VERSION ""

NS_ :

BU_: EBCM ADAS PCM EPS VSA SCM BDY XXX EPB EON

BO_ 145 KINEMATICS: 8 XXX
 SG_ LAT_ACCEL : 7|10@0+ (0.02,-512) [-20|20] "m/s2" EON

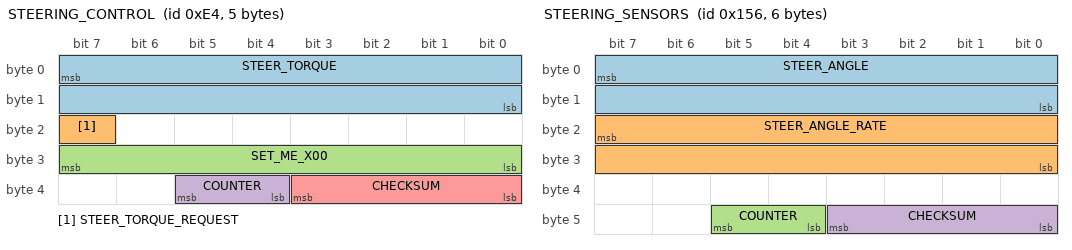
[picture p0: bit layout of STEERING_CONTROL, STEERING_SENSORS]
BO_ 228 STEERING_CONTROL: 5 ADAS
 SG_ STEER_TORQUE : 7|16@0- (1,0) [-3840|3840] "" EPS
 SG_ STEER_TORQUE_REQUEST : 23|1@0+ (1,0) [0|1] "" EPS
 SG_ SET_ME_X00 : 31|8@0+ (1,0) [0|0] "" EPS
 SG_ COUNTER : 37|2@0+ (1,0) [0|3] "" EPS
 SG_ CHECKSUM : 35|4@0+ (1,0) [0|3] "" EPS

//BO_ 304 GAS_PEDAL_2: 8 PCM
 //SG_ ENGINE_TORQUE_ESTIMATE : 7|16@0- (1,0) [-1000|1000] "Nm" EON
// SG_ ENGINE_TORQUE_REQUEST : 23|16@0- (1,0) [-1000|1000] "Nm" EON
// SG_ CAR_GAS : 39|8@0+ (1,0) [0|255] "" EON

BO_ 308 GAS_PEDAL_3: 8 XXX
 SG_ PEDAL_GAS_VARIANT : 19|12@0+ (1,0) [0|2048] "" XXX

BO_ 316 GAS_PEDAL: 8 PCM
 SG_ ENGINE_TORQUE_ESTIMATE : 7|16@0- (1,0) [-1000|1000] "Nm" EON
 SG_ ENGINE_TORQUE_REQUEST : 23|16@0- (1,0) [-1000|1000] "Nm" EON
 SG_ CAR_GAS : 39|8@0+ (1,0) [0|255] "" EON

BO_ 342 STEERING_SENSORS: 6 EPS
 SG_ STEER_ANGLE : 7|16@0- (-0.1,0) [-500|500] "deg" EON
 SG_ STEER_ANGLE_RATE : 23|16@0- (1,0) [-3000|3000] "deg/s" EON
 SG_ COUNTER : 45|2@0+ (1,0) [0|3] "" EON
 SG_ CHECKSUM : 43|4@0+ (1,0) [0|3] "" EON

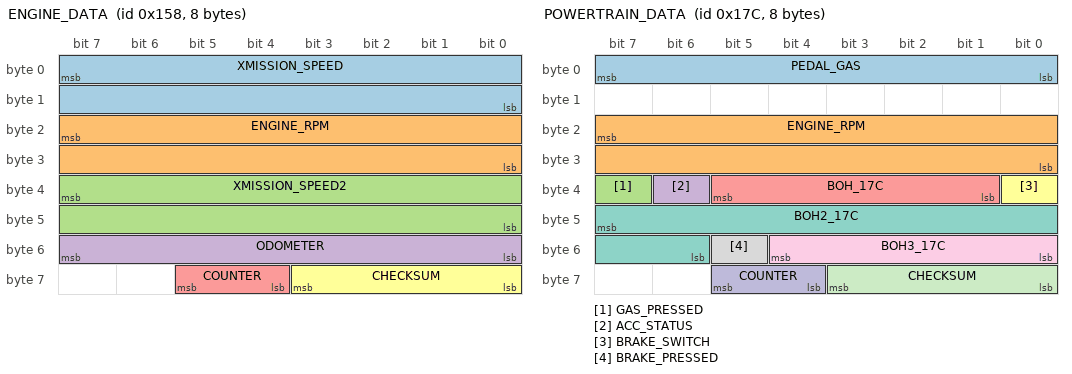
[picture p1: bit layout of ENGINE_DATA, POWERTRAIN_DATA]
BO_ 344 ENGINE_DATA: 8 PCM
 SG_ XMISSION_SPEED : 7|16@0+ (0.01,0) [0|250] "kph" EON
 SG_ ENGINE_RPM : 23|16@0+ (1,0) [0|15000] "rpm" EON
 SG_ XMISSION_SPEED2 : 39|16@0+ (0.01,0) [0|250] "kph" EON
 SG_ ODOMETER : 55|8@0+ (10,0) [0|2550] "m" XXX
 SG_ COUNTER : 61|2@0+ (1,0) [0|3] "" EON
 SG_ CHECKSUM : 59|4@0+ (1,0) [0|15] "" EON

BO_ 380 POWERTRAIN_DATA: 8 PCM
 SG_ PEDAL_GAS : 7|8@0+ (1,0) [0|255] "" EON
 SG_ ENGINE_RPM : 23|16@0+ (1,0) [0|15000] "rpm" EON
 SG_ GAS_PRESSED : 39|1@0+ (1,0) [0|1] "" EON
 SG_ ACC_STATUS : 38|1@0+ (1,0) [0|1] "rpm" EON
 SG_ BOH_17C : 37|5@0+ (1,0) [0|1] "rpm" EON
 SG_ BRAKE_SWITCH : 32|1@0+ (1,0) [0|1] "rpm" EON
 SG_ BOH2_17C : 47|10@0+ (1,0) [0|1] "rpm" EON
 SG_ BRAKE_PRESSED : 53|1@0+ (1,0) [0|1] "" EON
 SG_ BOH3_17C : 52|5@0+ (1,0) [0|1] "rpm" EON
 SG_ COUNTER : 61|2@0+ (1,0) [0|3] "" EON
 SG_ CHECKSUM : 59|4@0+ (1,0) [0|3] "" EON

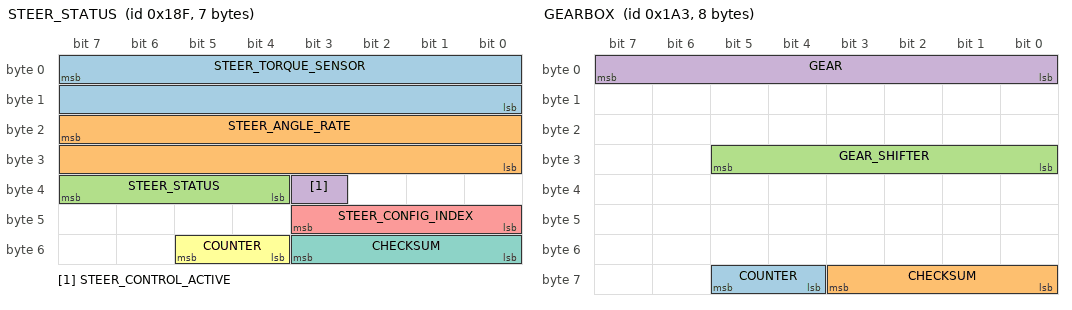
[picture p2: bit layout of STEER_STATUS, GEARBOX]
BO_ 399 STEER_STATUS: 7 EPS
 SG_ STEER_TORQUE_SENSOR : 7|16@0- (-1,0) [-31000|31000] "tbd" EON
 SG_ STEER_ANGLE_RATE : 23|16@0- (-0.1,0) [-31000|31000] "deg/s" EON
 SG_ STEER_STATUS : 39|4@0+ (1,0) [0|15] "" EON
 SG_ STEER_CONTROL_ACTIVE : 35|1@0+ (1,0) [0|1] "" EON
 SG_ STEER_CONFIG_INDEX : 43|4@0+ (1,0) [0|15] "" EON
 SG_ COUNTER : 53|2@0+ (1,0) [0|3] "" EON
 SG_ CHECKSUM : 51|4@0+ (1,0) [0|3] "" EON

BO_ 419 GEARBOX: 8 PCM
 SG_ COUNTER : 61|2@0+ (1,0) [0|3] "" EON
 SG_ CHECKSUM : 59|4@0+ (1,0) [0|3] "" EON
 SG_ GEAR_SHIFTER : 29|6@0+ (1,0) [0|63] "" EON
 SG_ GEAR : 7|8@0+ (1,0) [0|255] "" EON

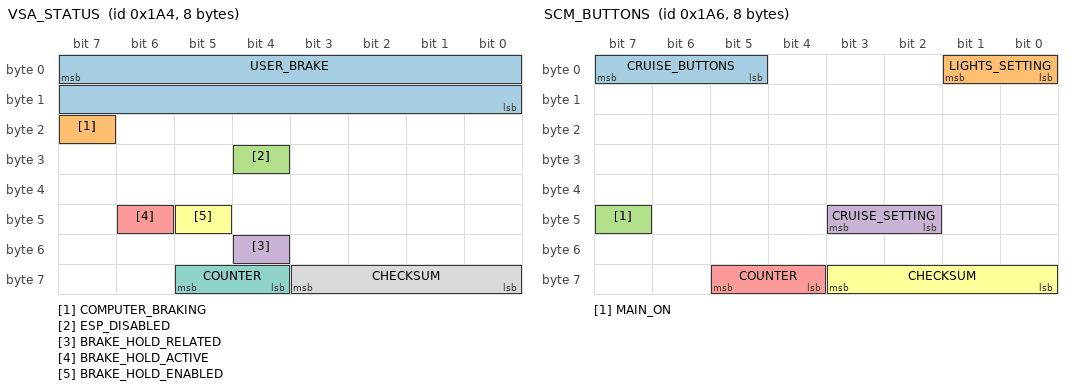
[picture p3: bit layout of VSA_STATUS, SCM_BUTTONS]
BO_ 420 VSA_STATUS: 8 VSA
 SG_ USER_BRAKE : 7|16@0+ (0.015625,-1.609375) [0|1000] "" EON
 SG_ COMPUTER_BRAKING : 23|1@0+ (1,0) [0|1] "" EON
 SG_ ESP_DISABLED : 28|1@0+ (1,0) [0|1] "" EON
 SG_ BRAKE_HOLD_RELATED : 52|1@0+ (1,0) [0|1] "" XXX
 SG_ BRAKE_HOLD_ACTIVE : 46|1@0+ (1,0) [0|1] "" EON
 SG_ BRAKE_HOLD_ENABLED : 45|1@0+ (1,0) [0|1] "" EON
 SG_ COUNTER : 61|2@0+ (1,0) [0|3] "" EON
 SG_ CHECKSUM : 59|4@0+ (1,0) [0|15] "" EON

BO_ 422 SCM_BUTTONS: 8 SCM
 SG_ CRUISE_BUTTONS : 7|3@0+ (1,0) [0|7] "" EON
 SG_ LIGHTS_SETTING : 1|2@0+ (1,0) [0|3] "" EON
 SG_ MAIN_ON : 47|1@0+ (1,0) [0|1] "" EON
 SG_ CRUISE_SETTING : 43|2@0+ (1,0) [0|3] "" EON
 SG_ COUNTER : 61|2@0+ (1,0) [0|3] "" EON
 SG_ CHECKSUM : 59|4@0+ (1,0) [0|3] "" EON

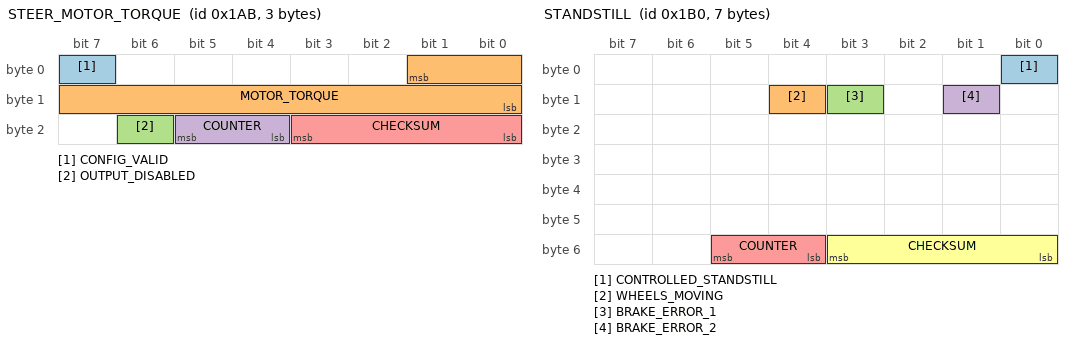
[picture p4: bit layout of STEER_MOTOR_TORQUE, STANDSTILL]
BO_ 427 STEER_MOTOR_TORQUE: 3 EPS
 SG_ CONFIG_VALID : 7|1@0+ (1,0) [0|1] "" EON
 SG_ MOTOR_TORQUE : 1|10@0+ (1,0) [0|256] "" EON
 SG_ OUTPUT_DISABLED : 22|1@0+ (1,0) [0|1] "" EON
 SG_ COUNTER : 21|2@0+ (1,0) [0|3] "" EON
 SG_ CHECKSUM : 19|4@0+ (1,0) [0|15] "" EON

BO_ 432 STANDSTILL: 7 VSA
 SG_ CONTROLLED_STANDSTILL : 0|1@0+ (1,0) [0|1] "" EON
 SG_ WHEELS_MOVING : 12|1@0+ (1,0) [0|1] "" EON
 SG_ BRAKE_ERROR_1 : 11|1@0+ (1,0) [0|1] "" EON
 SG_ BRAKE_ERROR_2 : 9|1@0+ (1,0) [0|1] "" EON
 SG_ COUNTER : 53|2@0+ (1,0) [0|3] "" EON
 SG_ CHECKSUM : 51|4@0+ (1,0) [0|3] "" EON

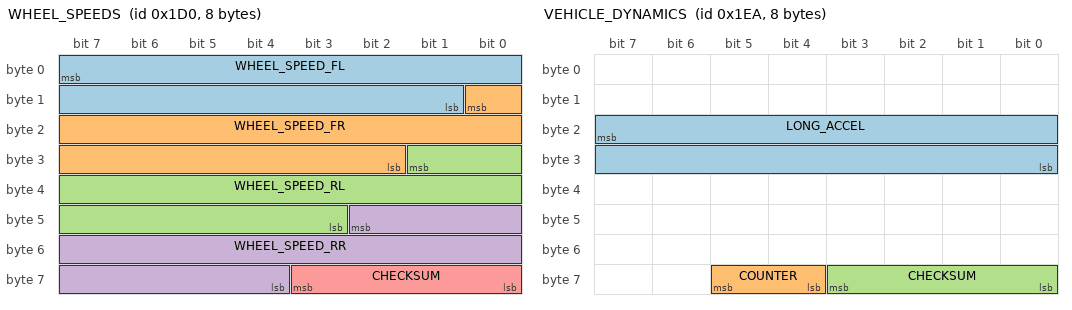
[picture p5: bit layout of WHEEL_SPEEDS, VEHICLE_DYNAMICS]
BO_ 464 WHEEL_SPEEDS: 8 VSA
 SG_ WHEEL_SPEED_FL : 7|15@0+ (0.01,0) [0|250] "kph" EON
 SG_ WHEEL_SPEED_FR : 8|15@0+ (0.01,0) [0|250] "kph" EON
 SG_ WHEEL_SPEED_RL : 25|15@0+ (0.01,0) [0|250] "kph" EON
 SG_ WHEEL_SPEED_RR : 42|15@0+ (0.01,0) [0|250] "kph" EON
 SG_ CHECKSUM : 59|4@0+ (1,0) [0|3] "" EON

BO_ 490 VEHICLE_DYNAMICS: 8 VSA
 SG_ LONG_ACCEL : 23|16@0- (0.0015384,0) [-20|20] "m/s2" EON
 SG_ COUNTER : 61|2@0+ (1,0) [0|3] "" EON
 SG_ CHECKSUM : 59|4@0+ (1,0) [0|3] "" EON

BO_ 506 BRAKE_COMMAND: 8 ADAS
 SG_ COMPUTER_BRAKE : 7|10@0+ (1,0) [0|1] "" EBCM
 SG_ SET_ME_X00 : 13|5@0+ (1,0) [0|1] "" EBCM
 SG_ BRAKE_PUMP_REQUEST : 8|1@0+ (1,0) [0|1] "" EBCM
 SG_ SET_ME_X00_2 : 23|3@0+ (1,0) [0|1] "" EBCM
 SG_ CRUISE_OVERRIDE : 20|1@0+ (1,0) [0|1] "" EBCM
 SG_ SET_ME_X00_3 : 19|1@0+ (1,0) [0|1] "" EBCM
 SG_ CRUISE_FAULT_CMD : 18|1@0+ (1,0) [0|1] "" EBCM
 SG_ CRUISE_CANCEL_CMD : 17|1@0+ (1,0) [0|1] "" EBCM
 SG_ COMPUTER_BRAKE_REQUEST : 16|1@0+ (1,0) [0|1] "" EBCM
 SG_ SET_ME_1 : 31|1@0+ (1,0) [0|1] "" EBCM
 SG_ AEB_REQ_1 : 29|1@0+ (1,0) [0|1] "" XXX
 SG_ AEB_REQ_2 : 26|3@0+ (1,0) [0|7] "" XXX
 SG_ BRAKE_LIGHTS : 39|1@0+ (1,0) [0|1] "" EBCM
 SG_ CRUISE_STATES : 38|7@0+ (1,0) [0|1] "" EBCM
 SG_ CHIME : 47|3@0+ (1,0) [0|7] "" EBCM
 SG_ SET_ME_X00_4 : 44|1@0+ (1,0) [0|1] "" EBCM
 SG_ FCW : 43|2@0+ (1,0) [0|3] "" EBCM
 SG_ AEB_STATUS : 41|2@0+ (1,0) [0|3] "" XXX
 SG_ SET_ME_X00_5 : 55|8@0+ (1,0) [0|0] "" EBCM
 SG_ COUNTER : 61|2@0+ (1,0) [0|3] "" EBCM
 SG_ CHECKSUM : 59|4@0+ (1,0) [0|15] "" EBCM

//BO_ 512 GAS_COMMAND: 6 EON
// SG_ GAS_COMMAND : 7|16@0+ (0.253984064,-83.3) [0|1] "" INTERCEPTOR
// SG_ GAS_COMMAND2 : 23|16@0+ (0.126992032,-83.3) [0|1] "" INTERCEPTOR
// SG_ ENABLE : 39|1@0+ (1,0) [0|1] "" INTERCEPTOR
// SG_ COUNTER_PEDAL : 35|4@0+ (1,0) [0|15] "" INTERCEPTOR
// SG_ CHECKSUM_PEDAL : 47|8@0+ (1,0) [0|255] "" INTERCEPTOR

//BO_ 513 GAS_SENSOR: 6 INTERCEPTOR
// SG_ INTERCEPTOR_GAS : 7|16@0+ (0.253984064,-83.3) [0|1] "" EON
 //SG_ INTERCEPTOR_GAS2 : 23|16@0+ (0.126992032,-83.3) [0|1] "" EON
// SG_ STATE : 39|4@0+ (1,0) [0|15] "" EON
// SG_ COUNTER_PEDAL : 35|4@0+ (1,0) [0|15] "" EON
// SG_ CHECKSUM_PEDAL : 47|8@0+ (1,0) [0|255] "" EON

//538 acceleration-ish

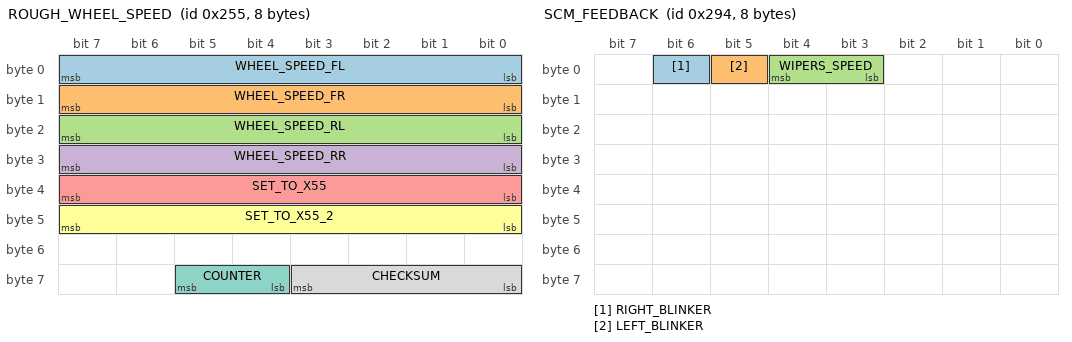
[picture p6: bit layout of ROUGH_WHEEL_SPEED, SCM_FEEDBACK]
BO_ 597 ROUGH_WHEEL_SPEED: 8 VSA
 SG_ WHEEL_SPEED_FL : 7|8@0+ (1,0) [0|255] "mph" EON
 SG_ WHEEL_SPEED_FR : 15|8@0+ (1,0) [0|255] "mph" EON
 SG_ WHEEL_SPEED_RL : 23|8@0+ (1,0) [0|255] "mph" EON
 SG_ WHEEL_SPEED_RR : 31|8@0+ (1,0) [0|255] "mph" EON
 SG_ SET_TO_X55 : 39|8@0+ (1,0) [0|255] "" EON
 SG_ SET_TO_X55_2 : 47|8@0+ (1,0) [0|255] "" EON
 SG_ COUNTER : 61|2@0+ (1,0) [0|3] "" EON
 SG_ CHECKSUM : 59|4@0+ (1,0) [0|15] "" EON

BO_ 660 SCM_FEEDBACK: 8 SCM
 SG_ RIGHT_BLINKER : 6|1@0+ (1,0) [0|1] "" EON
 SG_ LEFT_BLINKER : 5|1@0+ (1,0) [0|1] "" EON
 SG_ WIPERS_SPEED : 4|2@0+ (1,0) [0|3] "" EON

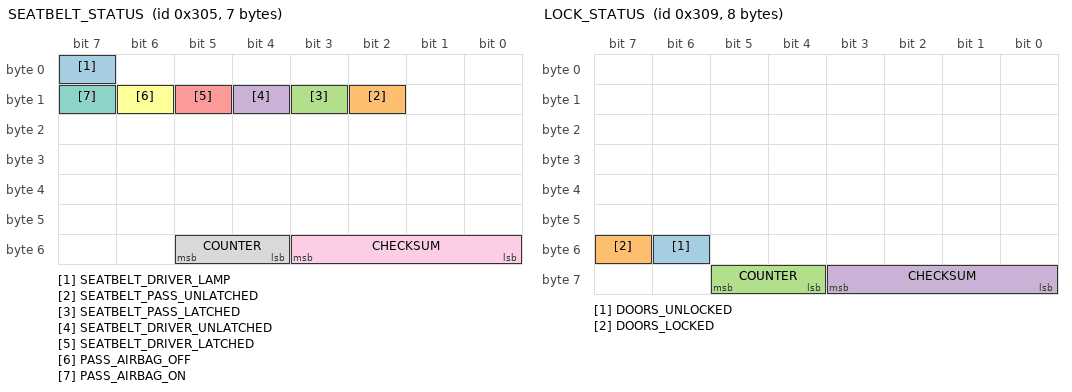
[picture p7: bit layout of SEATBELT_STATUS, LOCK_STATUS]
BO_ 773 SEATBELT_STATUS: 7 BDY
 SG_ SEATBELT_DRIVER_LAMP : 7|1@0+ (1,0) [0|1] "" EON
 SG_ SEATBELT_PASS_UNLATCHED : 10|1@0+ (1,0) [0|1] "" EON
 SG_ SEATBELT_PASS_LATCHED : 11|1@0+ (1,0) [0|1] "" EON
 SG_ SEATBELT_DRIVER_UNLATCHED : 12|1@0+ (1,0) [0|1] "" EON
 SG_ SEATBELT_DRIVER_LATCHED : 13|1@0+ (1,0) [0|1] "" EON
 SG_ PASS_AIRBAG_OFF : 14|1@0+ (1,0) [0|1] "" EON
 SG_ PASS_AIRBAG_ON : 15|1@0+ (1,0) [0|1] "" EON
 SG_ COUNTER : 53|2@0+ (1,0) [0|3] "" EON
 SG_ CHECKSUM : 51|4@0+ (1,0) [0|3] "" EON

BO_ 777 LOCK_STATUS: 8 XXX
 SG_ DOORS_UNLOCKED : 54|1@0+ (1,0) [0|1] "" EON
 SG_ DOORS_LOCKED : 55|1@0+ (1,0) [0|1] "" EON
 SG_ COUNTER : 61|2@0+ (1,0) [0|3] "" EON
 SG_ CHECKSUM : 59|4@0+ (1,0) [0|3] "" EON

BO_ 780 ACC_HUD: 8 ADAS
 SG_ PCM_SPEED : 7|16@0+ (0.01,0) [0|250] "kph" BDY
 SG_ PCM_GAS : 23|8@0+ (1,0) [0|127] "" BDY
 SG_ CRUISE_SPEED : 31|8@0+ (1,0) [0|255] "" BDY
 SG_ DTC_MODE : 39|1@0+ (1,0) [0|1] "" BDY
 SG_ BOH : 38|1@0+ (1,0) [0|1] "" BDY
 SG_ ACC_PROBLEM : 37|1@0+ (1,0) [0|1] "" BDY
 SG_ FCM_OFF : 36|1@0+ (1,0) [0|1] "" BDY
 SG_ FCM_OFF_2 : 35|1@0+ (1,0) [0|1] "" BDY
 SG_ FCM_PROBLEM : 34|1@0+ (1,0) [0|1] "" BDY
 SG_ RADAR_OBSTRUCTED : 33|1@0+ (1,0) [0|1] "" BDY
 SG_ ENABLE_MINI_CAR : 32|1@0+ (1,0) [0|1] "" BDY
 SG_ HUD_DISTANCE : 47|2@0+ (1,0) [0|3] "" BDY
 SG_ HUD_LEAD : 45|2@0+ (1,0) [0|3] "" BDY
 SG_ BOH_3 : 43|1@0+ (1,0) [0|3] "" BDY
 SG_ BOH_4 : 42|1@0+ (1,0) [0|3] "" BDY
 SG_ BOH_5 : 41|1@0+ (1,0) [0|3] "" BDY
 SG_ CRUISE_CONTROL_LABEL : 40|1@0+ (1,0) [0|3] "" BDY
 SG_ SET_ME_X01_2 : 55|1@0+ (1,0) [0|1] "" BDY
 SG_ IMPERIAL_UNIT : 54|1@0+ (1,0) [0|1] "" BDY
 SG_ HUD_DISTANCE_3 : 52|1@0+ (1,0) [0|1] "" BDY
 SG_ CHIME : 51|3@0+ (1,0) [0|1] "" BDY
 SG_ SET_ME_X01 : 48|1@0+ (1,0) [0|1] "" BDY
 SG_ ICONS : 63|2@0+ (1,0) [0|1] "" BDY
 SG_ COUNTER : 61|2@0+ (1,0) [0|3] "" BDY
 SG_ CHECKSUM : 59|4@0+ (1,0) [0|3] "" BDY

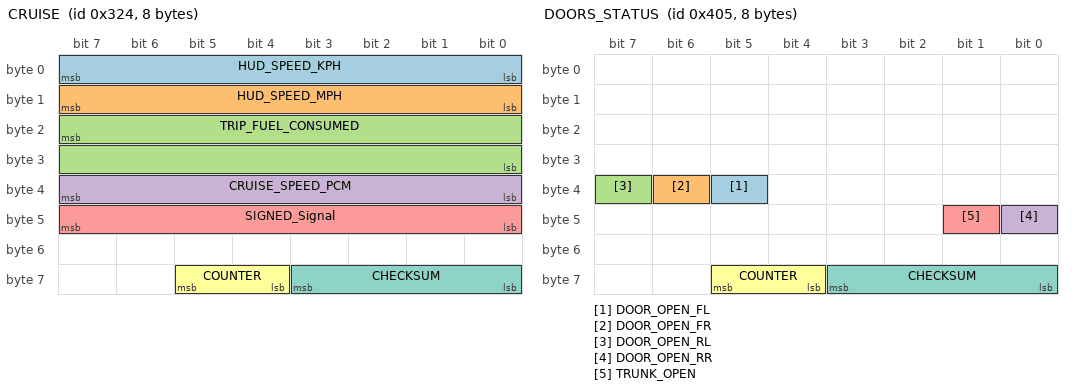
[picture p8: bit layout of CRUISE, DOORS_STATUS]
BO_ 804 CRUISE: 8 PCM
 SG_ HUD_SPEED_KPH : 7|8@0+ (1,0) [0|255] "kph" EON
 SG_ HUD_SPEED_MPH : 15|8@0+ (1,0) [0|255] "mph" EON
 SG_ TRIP_FUEL_CONSUMED : 23|16@0+ (1,0) [0|255] "" EON
 SG_ CRUISE_SPEED_PCM : 39|8@0+ (1,0) [0|255] "" EON
 SG_ SIGNED_Signal : 47|8@0- (1,0) [0|255] "" EON
// SG_ BOH3 : 55|8@0+ (1,0) [0|255] "" EON
 SG_ COUNTER : 61|2@0+ (1,0) [0|3] "" EON
 SG_ CHECKSUM : 59|4@0+ (1,0) [0|3] "" EON

BO_ 829 LKAS_HUD: 5 ADAS
 SG_ CAM_TEMP_HIGH : 7|1@0+ (1,0) [0|255] "" BDY
 SG_ SET_ME_X41 : 6|7@0+ (1,0) [0|127] "" BDY
 SG_ DASHED_LANES : 14|1@0+ (1,0) [0|1] "" BDY
 SG_ DTC : 13|1@0+ (1,0) [0|1] "" BDY
 SG_ LKAS_PROBLEM : 12|1@0+ (1,0) [0|1] "" BDY
 SG_ LKAS_OFF : 11|1@0+ (1,0) [0|1] "" BDY
 SG_ SOLID_LANES : 10|1@0+ (1,0) [0|1] "" BDY
 SG_ LDW_RIGHT : 9|1@0+ (1,0) [0|1] "" BDY
 SG_ STEERING_REQUIRED : 8|1@0+ (1,0) [0|1] "" BDY
 SG_ BOH : 23|2@0+ (1,0) [0|4] "" BDY
 SG_ LDW_PROBLEM : 21|1@0+ (1,0) [0|1] "" BDY
 SG_ BEEP : 17|2@0+ (1,0) [0|1] "" BDY
 SG_ LDW_ON : 28|1@0+ (1,0) [0|1] "" BDY
 SG_ LDW_OFF : 27|1@0+ (1,0) [0|1] "" BDY
 SG_ CLEAN_WINDSHIELD : 26|1@0+ (1,0) [0|1] "" BDY
 SG_ COUNTER : 37|2@0+ (1,0) [0|3] "" BDY
 SG_ CHECKSUM : 35|4@0+ (1,0) [0|15] "" BDY

//871 has stuff, MUXed, not sure what they represent. continuous signals.

BO_ 892 CRUISE_PARAMS: 8 PCM
 SG_ CRUISE_SPEED_OFFSET : 31|8@0- (0.1,0) [-128|127] "kph" EON
 SG_ CHECKSUM : 59|4@0+ (1,0) [0|3] "" EON
 SG_ COUNTER : 61|2@0+ (1,0) [0|3] "" EON

//BO_ 927 RADAR_HUD: 8 RADAR
// SG_ ZEROS_BOH : 7|10@0+ (1,0) [0|127] "" BDY
// SG_ CMBS_OFF : 12|1@0+ (1,0) [0|1] "" BDY
// SG_ RESUME_INSTRUCTION : 21|1@0+ (1,0) [0|1] "" XXX
// SG_ SET_TO_1 : 13|1@0+ (1,0) [0|1] "" BDY
// SG_ ZEROS_BOH2 : 11|4@0+ (1,0) [0|1] "" XXX
// SG_ APPLY_BRAKES_FOR_CANC : 23|1@0+ (1,0) [0|1] "" XXX
// SG_ ACC_ALERTS : 20|5@0+ (1,0) [0|1] "" BDY
 //SG_ SET_TO_0 : 22|1@0+ (1,0) [0|1] "" XXX
 //SG_ HUD_LEAD : 40|1@0+ (1,0) [0|1] "" XXX
// SG_ SET_TO_64 : 31|8@0+ (1,0) [0|255] "" XXX
// SG_ LEAD_DISTANCE : 39|8@0+ (1,0) [0|255] "" XXX
// SG_ ZEROS_BOH3 : 47|7@0+ (1,0) [0|127] "" XXX
// SG_ ZEROS_BOH4 : 55|8@0+ (1,0) [0|255] "" XXX
// SG_ COUNTER : 61|2@0+ (1,0) [0|3] "" XXX
// SG_ CHECKSUM : 59|4@0+ (1,0) [0|15] "" XXX

BO_ 1029 DOORS_STATUS: 8 BDY
  SG_ DOOR_OPEN_FL : 37|1@0+ (1,0) [0|1] "" EON
  SG_ DOOR_OPEN_FR : 38|1@0+ (1,0) [0|1] "" EON
  SG_ DOOR_OPEN_RL : 39|1@0+ (1,0) [0|1] "" EON
  SG_ DOOR_OPEN_RR : 40|1@0+ (1,0) [0|1] "" EON
  SG_ TRUNK_OPEN : 41|1@0+ (1,0) [0|1] "" EON
  SG_ COUNTER : 61|2@0+ (1,0) [0|3] "" EON
  SG_ CHECKSUM : 59|4@0+ (1,0) [0|3] "" EON

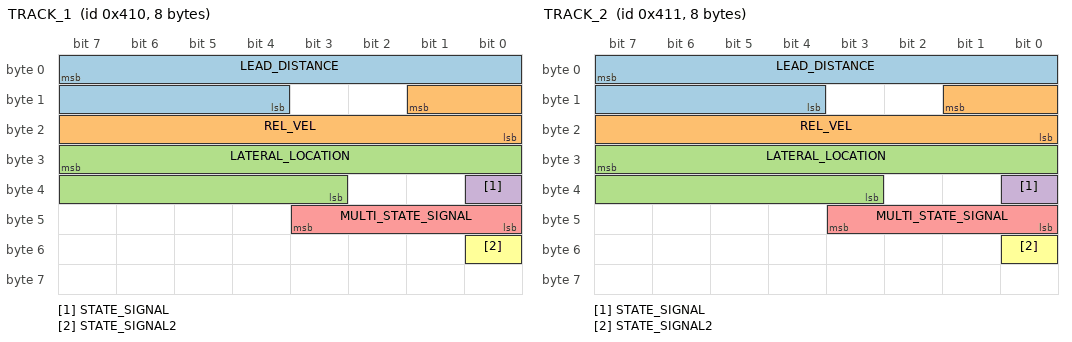
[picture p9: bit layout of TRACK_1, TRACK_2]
BO_ 1040 TRACK_1: 8 XXX
 SG_ LEAD_DISTANCE : 7|12@0+ (0.08,0) [0|255] "" XXX
 SG_ REL_VEL : 9|10@0- (0.05,0) [0|255] "" XXX
 SG_ LATERAL_LOCATION : 31|13@0- (0.08,0) [0|255] "" XXX
 SG_ STATE_SIGNAL : 32|1@0+ (1,0) [0|1] "" XXX
 SG_ MULTI_STATE_SIGNAL : 43|4@0+ (1,0) [0|16] "" XXX
 SG_ STATE_SIGNAL2 : 48|1@0+ (1,0) [0|1] "" XXX

BO_ 1041 TRACK_2: 8 XXX
 SG_ LEAD_DISTANCE : 7|12@0+ (0.08,0) [0|255] "" XXX
 SG_ REL_VEL : 9|10@0- (0.05,0) [0|255] "" XXX
 SG_ LATERAL_LOCATION : 31|13@0- (0.08,0) [0|255] "" XXX
 SG_ STATE_SIGNAL : 32|1@0+ (1,0) [0|1] "" XXX
 SG_ MULTI_STATE_SIGNAL : 43|4@0+ (1,0) [0|16] "" XXX
 SG_ STATE_SIGNAL2 : 48|1@0+ (1,0) [0|1] "" XXX

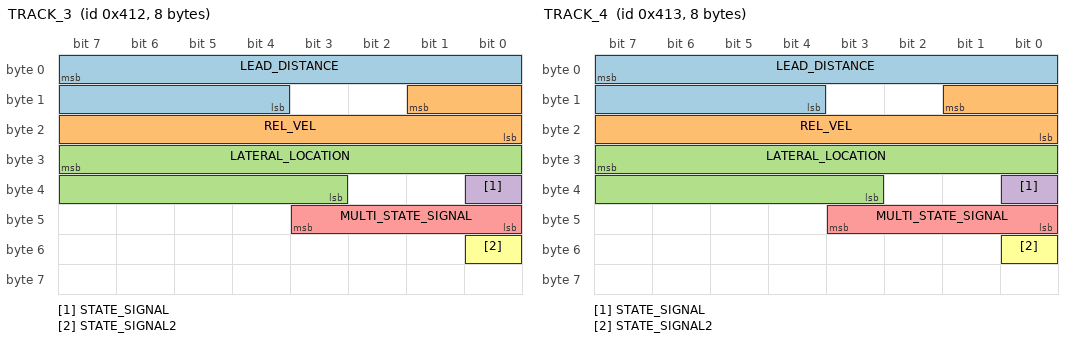
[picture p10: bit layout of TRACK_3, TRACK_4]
BO_ 1042 TRACK_3: 8 XXX
 SG_ LEAD_DISTANCE : 7|12@0+ (0.08,0) [0|255] "" XXX
 SG_ REL_VEL : 9|10@0- (0.05,0) [0|255] "" XXX
 SG_ LATERAL_LOCATION : 31|13@0- (0.08,0) [0|255] "" XXX
 SG_ STATE_SIGNAL : 32|1@0+ (1,0) [0|1] "" XXX
 SG_ MULTI_STATE_SIGNAL : 43|4@0+ (1,0) [0|16] "" XXX
 SG_ STATE_SIGNAL2 : 48|1@0+ (1,0) [0|1] "" XXX

BO_ 1043 TRACK_4: 8 XXX
 SG_ LEAD_DISTANCE : 7|12@0+ (0.08,0) [0|255] "" XXX
 SG_ REL_VEL : 9|10@0- (0.05,0) [0|255] "" XXX
 SG_ LATERAL_LOCATION : 31|13@0- (0.08,0) [0|255] "" XXX
 SG_ STATE_SIGNAL : 32|1@0+ (1,0) [0|1] "" XXX
 SG_ MULTI_STATE_SIGNAL : 43|4@0+ (1,0) [0|16] "" XXX
 SG_ STATE_SIGNAL2 : 48|1@0+ (1,0) [0|1] "" XXX

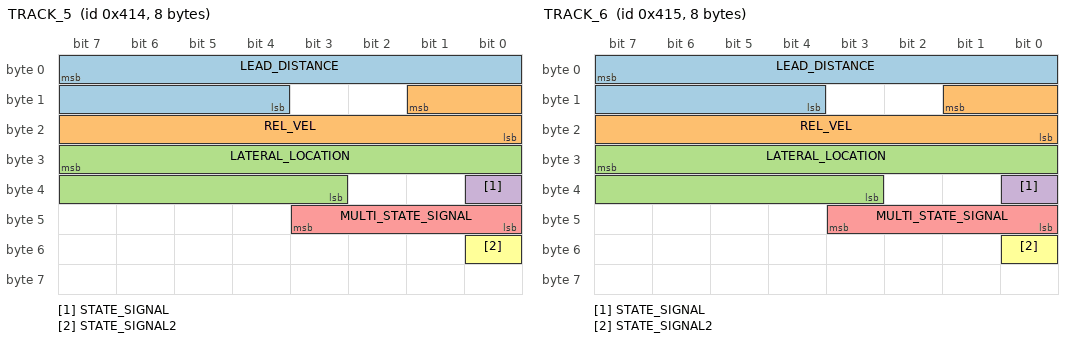
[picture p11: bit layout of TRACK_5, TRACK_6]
BO_ 1044 TRACK_5: 8 XXX
 SG_ LEAD_DISTANCE : 7|12@0+ (0.08,0) [0|255] "" XXX
 SG_ REL_VEL : 9|10@0- (0.05,0) [0|255] "" XXX
 SG_ LATERAL_LOCATION : 31|13@0- (0.08,0) [0|255] "" XXX
 SG_ STATE_SIGNAL : 32|1@0+ (1,0) [0|1] "" XXX
 SG_ MULTI_STATE_SIGNAL : 43|4@0+ (1,0) [0|16] "" XXX
 SG_ STATE_SIGNAL2 : 48|1@0+ (1,0) [0|1] "" XXX

BO_ 1045 TRACK_6: 8 XXX
	SG_ LEAD_DISTANCE : 7|12@0+ (0.08,0) [0|255] "" XXX
	SG_ REL_VEL : 9|10@0- (0.05,0) [0|255] "" XXX
	SG_ LATERAL_LOCATION : 31|13@0- (0.08,0) [0|255] "" XXX
	SG_ STATE_SIGNAL : 32|1@0+ (1,0) [0|1] "" XXX
	SG_ MULTI_STATE_SIGNAL : 43|4@0+ (1,0) [0|16] "" XXX
	SG_ STATE_SIGNAL2 : 48|1@0+ (1,0) [0|1] "" XXX

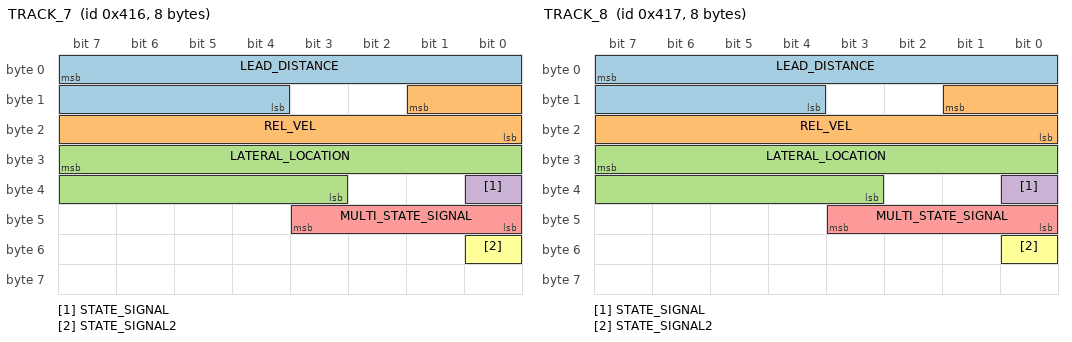
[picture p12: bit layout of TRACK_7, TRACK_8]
BO_ 1046 TRACK_7: 8 XXX
  SG_ LEAD_DISTANCE : 7|12@0+ (0.08,0) [0|255] "" XXX
  SG_ REL_VEL : 9|10@0- (0.05,0) [0|255] "" XXX
  SG_ LATERAL_LOCATION : 31|13@0- (0.08,0) [0|255] "" XXX
  SG_ STATE_SIGNAL : 32|1@0+ (1,0) [0|1] "" XXX
  SG_ MULTI_STATE_SIGNAL : 43|4@0+ (1,0) [0|16] "" XXX
  SG_ STATE_SIGNAL2 : 48|1@0+ (1,0) [0|1] "" XXX

BO_ 1047 TRACK_8: 8 XXX
  SG_ LEAD_DISTANCE : 7|12@0+ (0.08,0) [0|255] "" XXX
  SG_ REL_VEL : 9|10@0- (0.05,0) [0|255] "" XXX
  SG_ LATERAL_LOCATION : 31|13@0- (0.08,0) [0|255] "" XXX
  SG_ STATE_SIGNAL : 32|1@0+ (1,0) [0|1] "" XXX
  SG_ MULTI_STATE_SIGNAL : 43|4@0+ (1,0) [0|16] "" XXX
  SG_ STATE_SIGNAL2 : 48|1@0+ (1,0) [0|1] "" XXX

BO_ 1056 MESSAGE_NEW: 8 XXX
  SG_ REAL_SIGNAL_Discontinuity : 23|8@0+ (1,0) [0|255] "" XXX
	SG_ REAL_SIGNAL_Continuous : 31|12@0+ (1,0) [0|4096] "" XXX

//1057,1058,1059,1060 are similar

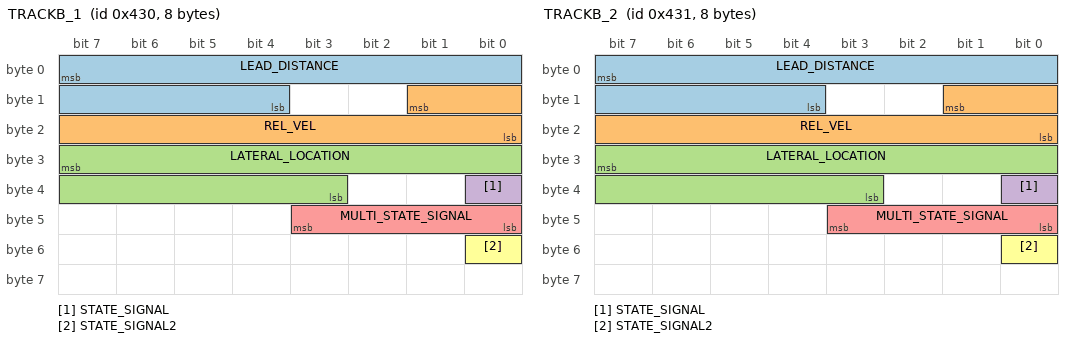
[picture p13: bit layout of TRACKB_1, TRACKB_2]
BO_ 1072 TRACKB_1: 8 XXX
	  SG_ LEAD_DISTANCE : 7|12@0+ (0.08,0) [0|255] "" XXX
	  SG_ REL_VEL : 9|10@0- (0.05,0) [0|255] "" XXX
	  SG_ LATERAL_LOCATION : 31|13@0- (0.08,0) [0|255] "" XXX
	  SG_ STATE_SIGNAL : 32|1@0+ (1,0) [0|1] "" XXX
	  SG_ MULTI_STATE_SIGNAL : 43|4@0+ (1,0) [0|16] "" XXX
	  SG_ STATE_SIGNAL2 : 48|1@0+ (1,0) [0|1] "" XXX

BO_ 1073 TRACKB_2: 8 XXX
	  SG_ LEAD_DISTANCE : 7|12@0+ (0.08,0) [0|255] "" XXX
	  SG_ REL_VEL : 9|10@0- (0.05,0) [0|255] "" XXX
	  SG_ LATERAL_LOCATION : 31|13@0- (0.08,0) [0|255] "" XXX
	  SG_ STATE_SIGNAL : 32|1@0+ (1,0) [0|1] "" XXX
	  SG_ MULTI_STATE_SIGNAL : 43|4@0+ (1,0) [0|16] "" XXX
	  SG_ STATE_SIGNAL2 : 48|1@0+ (1,0) [0|1] "" XXX

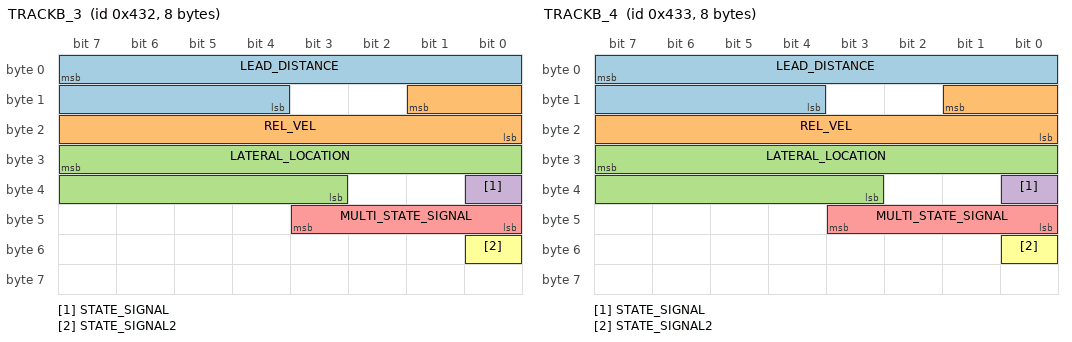
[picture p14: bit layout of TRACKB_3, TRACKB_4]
BO_ 1074 TRACKB_3: 8 XXX
	  SG_ LEAD_DISTANCE : 7|12@0+ (0.08,0) [0|255] "" XXX
	  SG_ REL_VEL : 9|10@0- (0.05,0) [0|255] "" XXX
	  SG_ LATERAL_LOCATION : 31|13@0- (0.08,0) [0|255] "" XXX
	  SG_ STATE_SIGNAL : 32|1@0+ (1,0) [0|1] "" XXX
	  SG_ MULTI_STATE_SIGNAL : 43|4@0+ (1,0) [0|16] "" XXX
	  SG_ STATE_SIGNAL2 : 48|1@0+ (1,0) [0|1] "" XXX

BO_ 1075 TRACKB_4: 8 XXX
	  SG_ LEAD_DISTANCE : 7|12@0+ (0.08,0) [0|255] "" XXX
	  SG_ REL_VEL : 9|10@0- (0.05,0) [0|255] "" XXX
	  SG_ LATERAL_LOCATION : 31|13@0- (0.08,0) [0|255] "" XXX
	  SG_ STATE_SIGNAL : 32|1@0+ (1,0) [0|1] "" XXX
	  SG_ MULTI_STATE_SIGNAL : 43|4@0+ (1,0) [0|16] "" XXX
	  SG_ STATE_SIGNAL2 : 48|1@0+ (1,0) [0|1] "" XXX

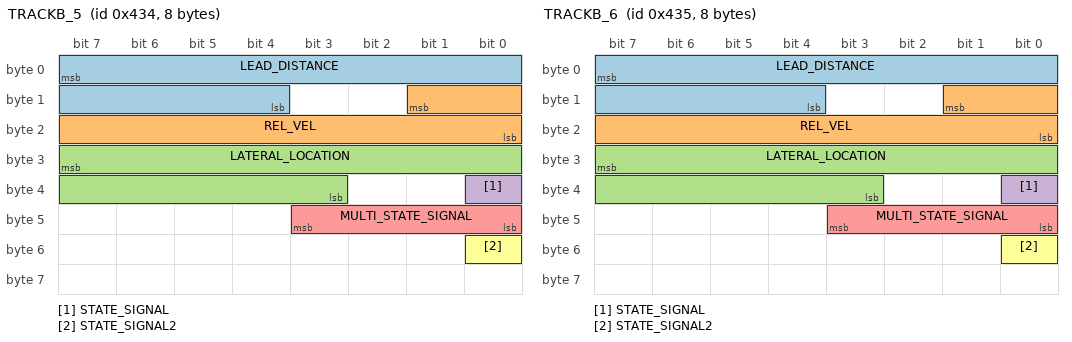
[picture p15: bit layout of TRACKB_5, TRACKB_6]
BO_ 1076 TRACKB_5: 8 XXX
	  SG_ LEAD_DISTANCE : 7|12@0+ (0.08,0) [0|255] "" XXX
	  SG_ REL_VEL : 9|10@0- (0.05,0) [0|255] "" XXX
	  SG_ LATERAL_LOCATION : 31|13@0- (0.08,0) [0|255] "" XXX
	  SG_ STATE_SIGNAL : 32|1@0+ (1,0) [0|1] "" XXX
	  SG_ MULTI_STATE_SIGNAL : 43|4@0+ (1,0) [0|16] "" XXX
	  SG_ STATE_SIGNAL2 : 48|1@0+ (1,0) [0|1] "" XXX

BO_ 1077 TRACKB_6: 8 XXX
	  SG_ LEAD_DISTANCE : 7|12@0+ (0.08,0) [0|255] "" XXX
	  SG_ REL_VEL : 9|10@0- (0.05,0) [0|255] "" XXX
	  SG_ LATERAL_LOCATION : 31|13@0- (0.08,0) [0|255] "" XXX
	  SG_ STATE_SIGNAL : 32|1@0+ (1,0) [0|1] "" XXX
	  SG_ MULTI_STATE_SIGNAL : 43|4@0+ (1,0) [0|16] "" XXX
	  SG_ STATE_SIGNAL2 : 48|1@0+ (1,0) [0|1] "" XXX

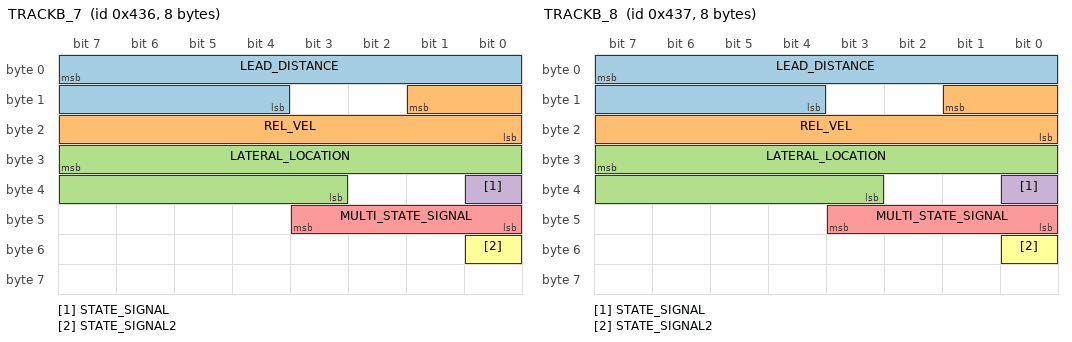
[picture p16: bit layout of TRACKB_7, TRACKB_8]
BO_ 1078 TRACKB_7: 8 XXX
	  SG_ LEAD_DISTANCE : 7|12@0+ (0.08,0) [0|255] "" XXX
	  SG_ REL_VEL : 9|10@0- (0.05,0) [0|255] "" XXX
	  SG_ LATERAL_LOCATION : 31|13@0- (0.08,0) [0|255] "" XXX
	  SG_ STATE_SIGNAL : 32|1@0+ (1,0) [0|1] "" XXX
	  SG_ MULTI_STATE_SIGNAL : 43|4@0+ (1,0) [0|16] "" XXX
	  SG_ STATE_SIGNAL2 : 48|1@0+ (1,0) [0|1] "" XXX

BO_ 1079 TRACKB_8: 8 XXX
	  SG_ LEAD_DISTANCE : 7|12@0+ (0.08,0) [0|255] "" XXX
	  SG_ REL_VEL : 9|10@0- (0.05,0) [0|255] "" XXX
	  SG_ LATERAL_LOCATION : 31|13@0- (0.08,0) [0|255] "" XXX
	  SG_ STATE_SIGNAL : 32|1@0+ (1,0) [0|1] "" XXX
	  SG_ MULTI_STATE_SIGNAL : 43|4@0+ (1,0) [0|16] "" XXX
	  SG_ STATE_SIGNAL2 : 48|1@0+ (1,0) [0|1] "" XXX

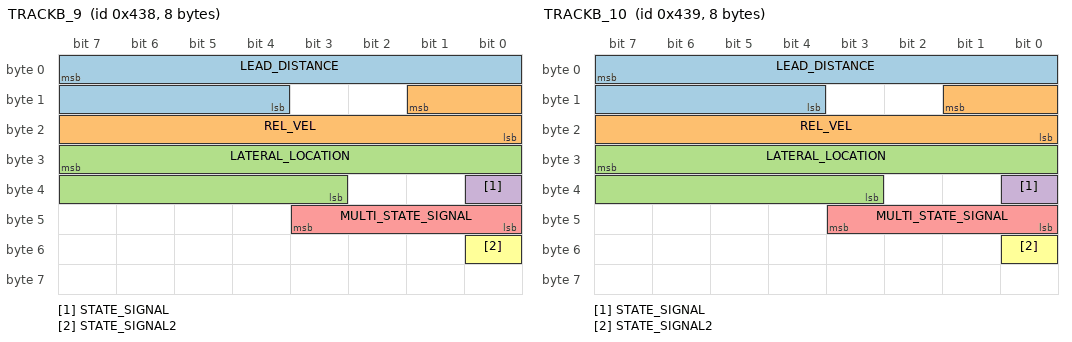
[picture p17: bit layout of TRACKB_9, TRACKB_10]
BO_ 1080 TRACKB_9: 8 XXX
	  SG_ LEAD_DISTANCE : 7|12@0+ (0.08,0) [0|255] "" XXX
	  SG_ REL_VEL : 9|10@0- (0.05,0) [0|255] "" XXX
	  SG_ LATERAL_LOCATION : 31|13@0- (0.08,0) [0|255] "" XXX
	  SG_ STATE_SIGNAL : 32|1@0+ (1,0) [0|1] "" XXX
	  SG_ MULTI_STATE_SIGNAL : 43|4@0+ (1,0) [0|16] "" XXX
	  SG_ STATE_SIGNAL2 : 48|1@0+ (1,0) [0|1] "" XXX

BO_ 1081 TRACKB_10: 8 XXX
	  SG_ LEAD_DISTANCE : 7|12@0+ (0.08,0) [0|255] "" XXX
	  SG_ REL_VEL : 9|10@0- (0.05,0) [0|255] "" XXX
	  SG_ LATERAL_LOCATION : 31|13@0- (0.08,0) [0|255] "" XXX
	  SG_ STATE_SIGNAL : 32|1@0+ (1,0) [0|1] "" XXX
	  SG_ MULTI_STATE_SIGNAL : 43|4@0+ (1,0) [0|16] "" XXX
	  SG_ STATE_SIGNAL2 : 48|1@0+ (1,0) [0|1] "" XXX

//1088, 1089 MUX, bus 1 has data on same radar data signals, bus 0/2 has static values

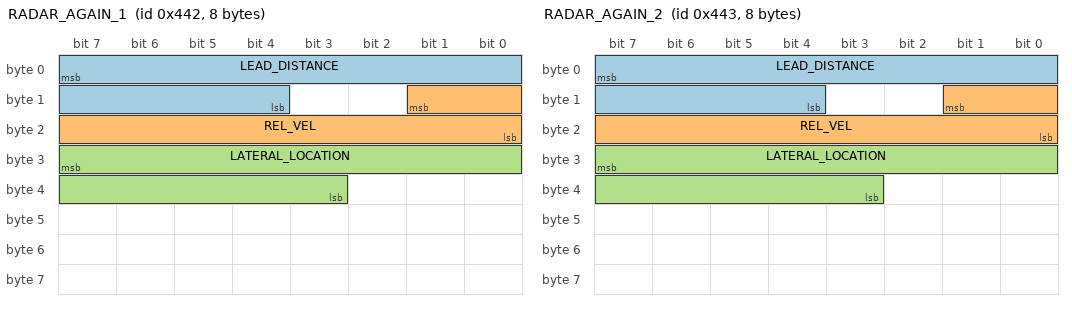
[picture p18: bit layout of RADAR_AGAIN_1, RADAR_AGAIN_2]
BO_ 1090 RADAR_AGAIN_1: 8 XXX
 SG_ LEAD_DISTANCE : 7|12@0+ (0.08,0) [0|255] "" XXX
 SG_ REL_VEL : 9|10@0- (0.05,0) [0|255] "" XXX
 SG_ LATERAL_LOCATION : 31|13@0- (0.08,0) [0|255] "" XXX

BO_ 1091 RADAR_AGAIN_2: 8 XXX
  SG_ LEAD_DISTANCE : 7|12@0+ (0.08,0) [0|255] "" XXX
  SG_ REL_VEL : 9|10@0- (0.05,0) [0|255] "" XXX
  SG_ LATERAL_LOCATION : 31|13@0- (0.08,0) [0|255] "" XXX

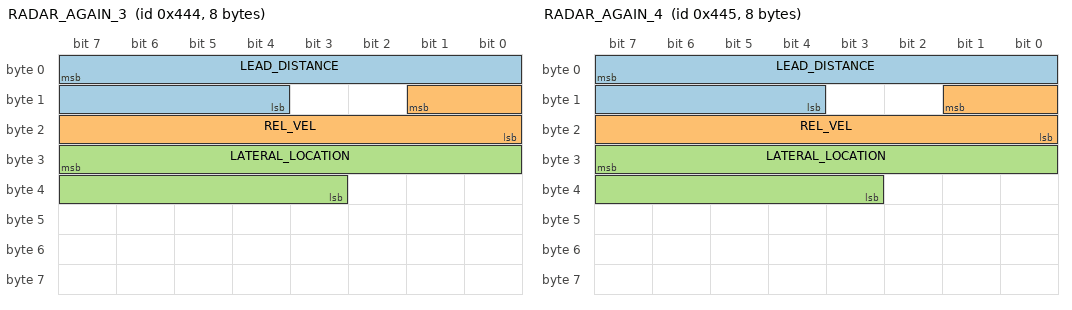
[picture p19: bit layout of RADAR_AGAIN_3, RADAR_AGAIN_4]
BO_ 1092 RADAR_AGAIN_3: 8 XXX
	 SG_ LEAD_DISTANCE : 7|12@0+ (0.08,0) [0|255] "" XXX
	 SG_ REL_VEL : 9|10@0- (0.05,0) [0|255] "" XXX
	 SG_ LATERAL_LOCATION : 31|13@0- (0.08,0) [0|255] "" XXX

BO_ 1093 RADAR_AGAIN_4: 8 XXX
	  SG_ LEAD_DISTANCE : 7|12@0+ (0.08,0) [0|255] "" XXX
	  SG_ REL_VEL : 9|10@0- (0.05,0) [0|255] "" XXX
	  SG_ LATERAL_LOCATION : 31|13@0- (0.08,0) [0|255] "" XXX

BO_ 1279 INT_SPEED: 8 XXX
 SG_ INT_SPEED : 15|8@0+ (1,0) [0|255] "" XXX
 SG_ SIGNED_SIGNAL : 23|16@0- (1,0) [0|255] "" XXX
//could the signed signal be acceleration related?

VAL_ 399 STEER_STATUS 6 "tmp_fault" 5 "fault_1" 4 "no_torque_alert_2" 3 "low_speed_lockout" 2 "no_torque_alert_1" 0 "normal" ;
VAL_ 419 GEAR_SHIFTER  32 "D" 8 "R" 4 "P" ;
VAL_ 422 CRUISE_BUTTONS 7 "tbd7" 6 "tbd6" 5 "tbd5" 4 "resume" 3 "set" 2 "cancel" 1 "system_toggle" 0 "none" ;
VAL_ 422 LIGHTS_SETTING 3 "high_beam" 2 "low_beam" 1 "position" 0 "no_lights" ;
VAL_ 422 CRUISE_SETTING 3 "distance_adj" 2 "tbd" 1 "lkas_button" 0 "none" ;
VAL_ 513 STATE 5 "FAULT_TIMEOUT" 4 "FAULT_STARTUP" 3 "FAULT_SCE" 2 "FAULT_SEND" 1 "FAULT_BAD_CHECKSUM" 0 "NO_FAULT" ;

CM_ "CHFFR_METRIC 342 STEER_ANGLE STEER_ANGLE 0.36 180; CHFFR_METRIC 380 ENGINE_RPM ENGINE_RPM 1 0; CHFFR_METRIC 804 ENGINE_TEMPERATURE ENGINE_TEMPERATURE 1 0";
CM_ SG_ 490 LONG_ACCEL "wheel speed derivative, noisy and zero snapping";
CM_ SG_ 506 AEB_REQ_1 "set for duration of suspected AEB event";
CM_ SG_ 773 PASS_AIRBAG_ON "Might just be indicator light";
CM_ SG_ 773 PASS_AIRBAG_OFF "Might just be indicator light";
CM_ SG_ 780 CRUISE_SPEED "255 = no speed";
CM_ SG_ 804 CRUISE_SPEED_PCM "255 = no speed";
CM_ SG_ 829 BEEP "beeps are pleasant, chimes are for warnngs etc...";

VAL_ 506 FCW 3 "fcw" 2 "fcw" 1 "fcw" 0 "no_fcw" ;
VAL_ 506 CHIME 4 "double_chime" 3 "single_chime" 2 "continuous_chime" 1 "repeating_chime" 0 "no_chime" ;
VAL_ 506 AEB_STATUS 3 "aeb_prepare" 2 "aeb_ready" 1 "aeb_braking" 0 "no_aeb" ;
VAL_ 780 CRUISE_SPEED 255 "no_speed" 252 "stopped" ;
VAL_ 780 HUD_LEAD 3 "acc_off" 2 "solid_car" 1 "dashed_car" 0 "no_car" ;
VAL_ 829 BEEP 3 "single_beep" 2 "triple_beep" 1 "repeated_beep" 0 "no_beep" ;
VAL_ 513 STATE 5 "FAULT_TIMEOUT" 4 "FAULT_STARTUP" 3 "FAULT_SCE" 2 "FAULT_SEND" 1 "FAULT_BAD_CHECKSUM" 0 "NO_FAULT" ;
